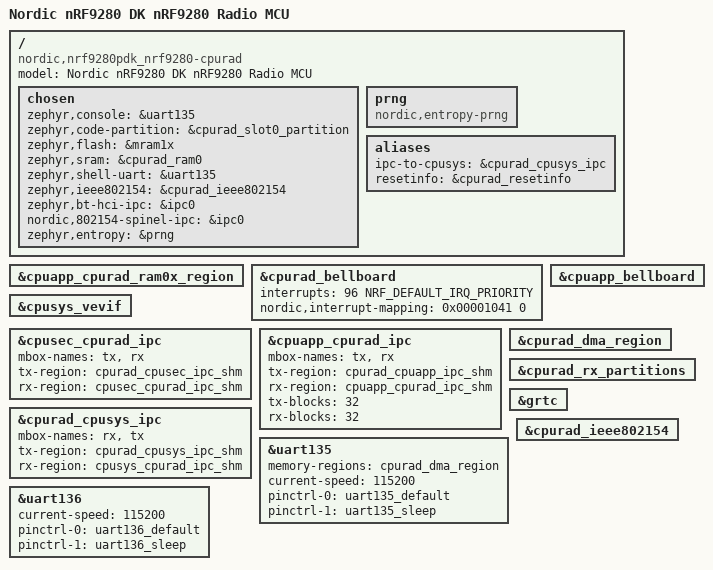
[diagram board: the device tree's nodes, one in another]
/*
 * Copyright (c) 2024 Nordic Semiconductor ASA
 *
 * SPDX-License-Identifier: Apache-2.0
 */

/dts-v1/;

#include <nordic/nrf9280_cpurad.dtsi>
#include "nrf9280pdk_nrf9280-memory_map.dtsi"
#include "nrf9280pdk_nrf9280-ipc_conf.dtsi"
#include "nrf9280pdk_nrf9280-pinctrl.dtsi"

/delete-node/ &cpuapp_cpuppr_ipc;
/delete-node/ &cpuapp_cpusys_ipc;
/delete-node/ &cpusec_cpuapp_ipc;

/ {
	compatible = "nordic,nrf9280pdk_nrf9280-cpurad";
	model = "Nordic nRF9280 DK nRF9280 Radio MCU";

	chosen {
		zephyr,console = &uart135;
		zephyr,code-partition = &cpurad_slot0_partition;
		zephyr,flash = &mram1x;
		zephyr,sram = &cpurad_ram0;
		zephyr,shell-uart = &uart135;
		zephyr,ieee802154 = &cpurad_ieee802154;
		zephyr,bt-hci-ipc = &ipc0;
		nordic,802154-spinel-ipc = &ipc0;
		zephyr,entropy = &prng;
	};
	prng: prng {
		compatible = "nordic,entropy-prng";
		status = "okay";
	};
	aliases {
		ipc-to-cpusys = &cpurad_cpusys_ipc;
		resetinfo = &cpurad_resetinfo;
	};
};

&cpuapp_cpurad_ram0x_region {
	status = "okay";
};

&cpurad_bellboard {
	status = "okay";
	interrupts = <96 NRF_DEFAULT_IRQ_PRIORITY>;
	interrupt-names = "irq0";
	/* The following bells on this bellboard are rang by these cores
	 *  - Bell 0: cpusec
	 *  - Bell 6: cpusys
	 *  - Bell 12: cpuapp
	 */
	nordic,interrupt-mapping = <0x00001041 0>;
};

&cpuapp_bellboard {
	status = "okay";
};

&cpusys_vevif {
	status = "okay";
};

&cpusec_cpurad_ipc {
	mbox-names = "tx", "rx";
	tx-region = <&cpurad_cpusec_ipc_shm>;
	rx-region = <&cpusec_cpurad_ipc_shm>;
};

ipc0: &cpuapp_cpurad_ipc {
	status = "okay";
	mbox-names = "tx", "rx";
	tx-region = <&cpurad_cpuapp_ipc_shm>;
	rx-region = <&cpuapp_cpurad_ipc_shm>;
	tx-blocks = <32>;
	rx-blocks = <32>;
};

&cpurad_cpusys_ipc {
	status = "okay";
	mbox-names = "rx", "tx";
	tx-region = <&cpurad_cpusys_ipc_shm>;
	rx-region = <&cpusys_cpurad_ipc_shm>;
};

&cpurad_dma_region {
	status = "okay";
};

&cpurad_rx_partitions {
	status = "okay";
};

&grtc {
	status = "okay";
};

&uart135 {
	status = "okay";
	memory-regions = <&cpurad_dma_region>;
	current-speed = <115200>;
	pinctrl-0 = <&uart135_default>;
	pinctrl-1 = <&uart135_sleep>;
	pinctrl-names = "default", "sleep";
};

&uart136 {
	current-speed = <115200>;
	pinctrl-0 = <&uart136_default>;
	pinctrl-1 = <&uart136_sleep>;
	pinctrl-names = "default", "sleep";
};

&cpurad_ieee802154 {
	status = "okay";
};
